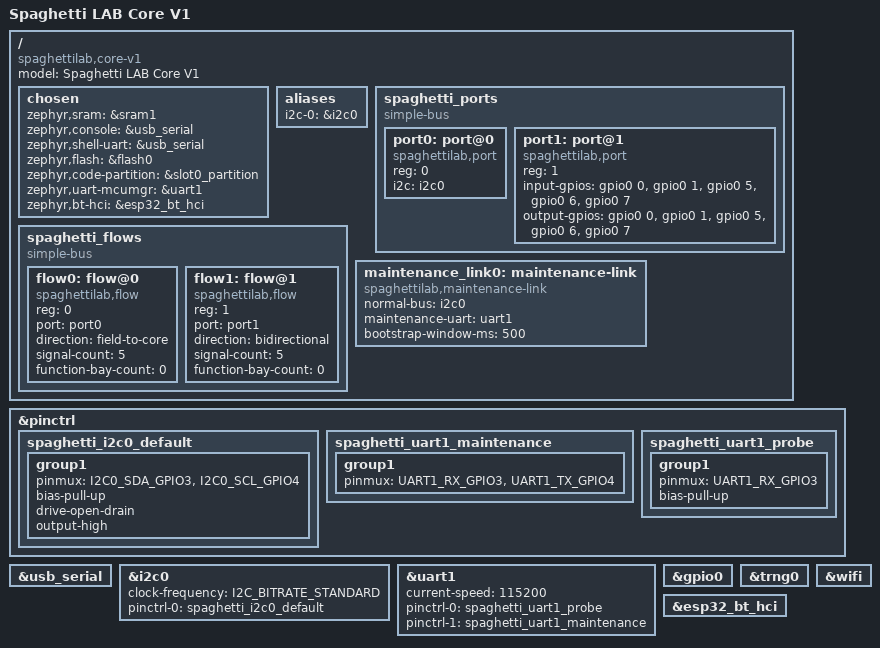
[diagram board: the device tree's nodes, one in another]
/dts-v1/;

#include <espressif/esp32c3/esp32c3_mini_n4.dtsi>
#include <espressif/partitions_0x0_default.dtsi>
#include <zephyr/dt-bindings/pinctrl/esp-pinctrl-common.h>
#include <zephyr/dt-bindings/pinctrl/esp32c3-pinctrl.h>
#include <zephyr/dt-bindings/pinctrl/esp32c3-gpio-sigmap.h>

/ {
	model = "Spaghetti LAB Core V1";
	compatible = "spaghettilab,core-v1", "espressif,esp32c3";

	chosen {
		zephyr,sram = &sram1;
		zephyr,console = &usb_serial;
		zephyr,shell-uart = &usb_serial;
		zephyr,flash = &flash0;
		zephyr,code-partition = &slot0_partition;
		zephyr,uart-mcumgr = &uart1;
		zephyr,bt-hci = &esp32_bt_hci;
	};

	aliases {
		i2c-0 = &i2c0;
	};

	spaghetti_ports {
		compatible = "simple-bus";
		#address-cells = <1>;
		#size-cells = <0>;

		port0: port@0 {
			compatible = "spaghettilab,port";
			reg = <0>;
			i2c = <&i2c0>;
			status = "okay";
		};

		/*
		 * A second connector exposing five raw digital signal lines on
		 * ESP32-C3 SuperMini breakout pins 0, 1, 5, 6, 7 — every
		 * production pin reference here is the SuperMini's own labeled
		 * breakout pin, chosen deliberately excluding the pins already
		 * wired above (GPIO3/GPIO4, I2C0) and GPIO2/GPIO8/GPIO9 (ESP32-C3
		 * strapping pins, sampled by the boot ROM at reset to select
		 * flash voltage/download mode — safe to use as GPIO once running,
		 * but risky to wire to anything that could hold them low across a
		 * reset). Each line is both an input-gpios and output-gpios entry
		 * at the same signal index: the physical pin is bidirectional,
		 * which direction is actually used is a Module driver's own
		 * choice (its declared required_capabilities), not fixed here.
		 */
		port1: port@1 {
			compatible = "spaghettilab,port";
			reg = <1>;
			input-gpios = <&gpio0 0 GPIO_ACTIVE_HIGH>,
				      <&gpio0 1 GPIO_ACTIVE_HIGH>,
				      <&gpio0 5 GPIO_ACTIVE_HIGH>,
				      <&gpio0 6 GPIO_ACTIVE_HIGH>,
				      <&gpio0 7 GPIO_ACTIVE_HIGH>;
			output-gpios = <&gpio0 0 GPIO_ACTIVE_HIGH>,
				       <&gpio0 1 GPIO_ACTIVE_HIGH>,
				       <&gpio0 5 GPIO_ACTIVE_HIGH>,
				       <&gpio0 6 GPIO_ACTIVE_HIGH>,
				       <&gpio0 7 GPIO_ACTIVE_HIGH>;
			status = "okay";
		};
	};

	spaghetti_flows {
		compatible = "simple-bus";
		#address-cells = <1>;
		#size-cells = <0>;

		flow0: flow@0 {
			compatible = "spaghettilab,flow";
			reg = <0>;
			port = <&port0>;
			direction = "field-to-core";
			signal-count = <5>;
			function-bay-count = <0>;
			status = "okay";
		};

		flow1: flow@1 {
			compatible = "spaghettilab,flow";
			reg = <1>;
			port = <&port1>;
			direction = "bidirectional";
			signal-count = <5>;
			function-bay-count = <0>;
			status = "okay";
		};
	};

	maintenance_link0: maintenance-link {
		compatible = "spaghettilab,maintenance-link";
		normal-bus = <&i2c0>;
		maintenance-uart = <&uart1>;
		bootstrap-window-ms = <500>;
		status = "okay";
	};
};

&pinctrl {
	spaghetti_i2c0_default: spaghetti_i2c0_default {
		group1 {
			pinmux = <I2C0_SDA_GPIO3>, <I2C0_SCL_GPIO4>;
			bias-pull-up;
			drive-open-drain;
			output-high;
		};
	};

	spaghetti_uart1_maintenance: spaghetti_uart1_maintenance {
		group1 {
			pinmux = <UART1_RX_GPIO3>, <UART1_TX_GPIO4>;
		};
	};

	spaghetti_uart1_probe: spaghetti_uart1_probe {
		group1 {
			pinmux = <UART1_RX_GPIO3>;
			bias-pull-up;
		};
	};
};

&usb_serial {
	status = "okay";
};

&i2c0 {
	status = "okay";
	clock-frequency = <I2C_BITRATE_STANDARD>;
	pinctrl-0 = <&spaghetti_i2c0_default>;
	pinctrl-names = "default";
};

&uart1 {
	status = "okay";
	current-speed = <115200>;
	pinctrl-0 = <&spaghetti_uart1_probe>;
	pinctrl-1 = <&spaghetti_uart1_maintenance>;
	pinctrl-names = "default", "sleep";
};

&gpio0 {
	status = "okay";
};

&trng0 {
	status = "okay";
};

&wifi {
	status = "okay";
};

&esp32_bt_hci {
	status = "okay";
};
